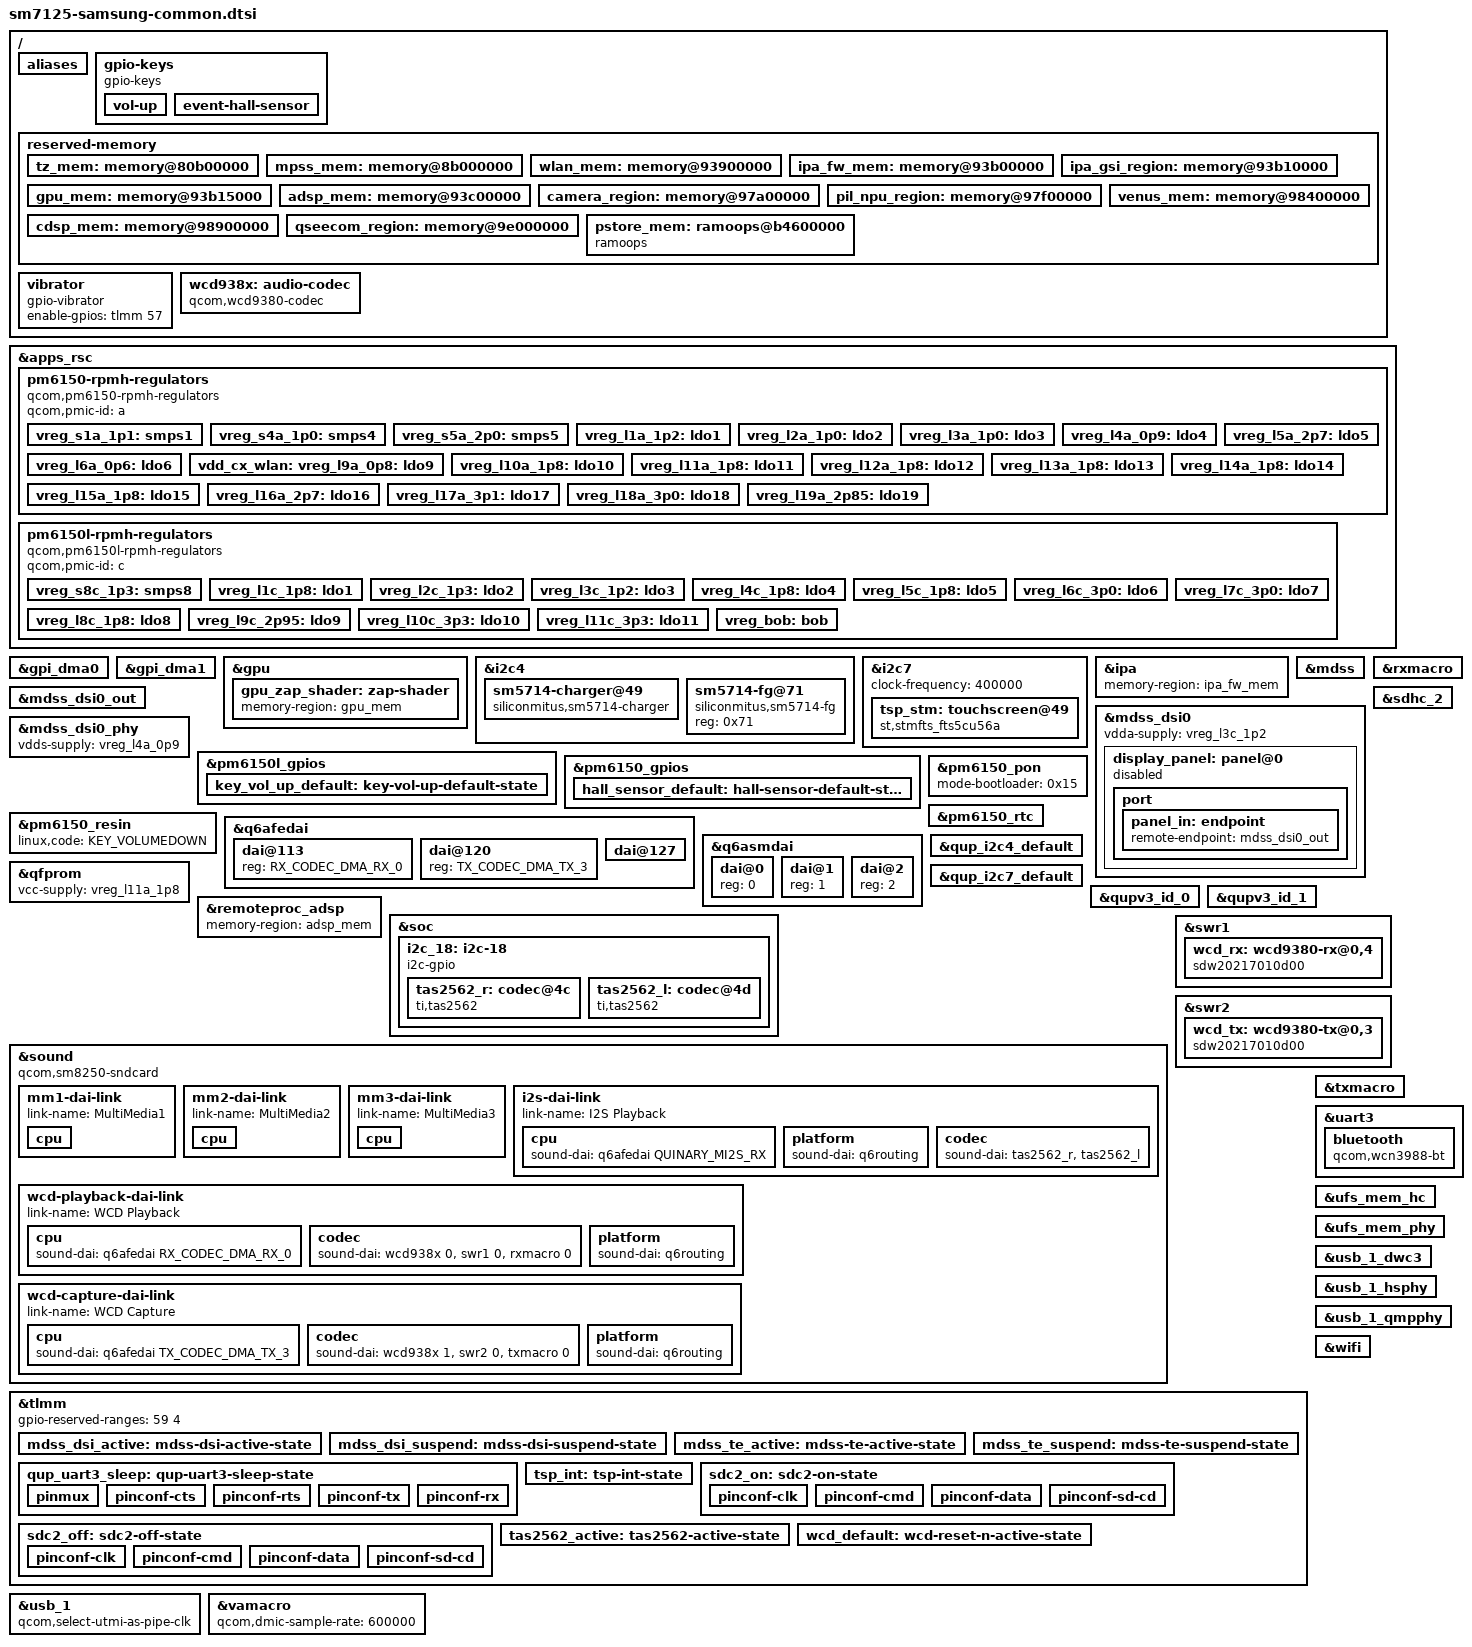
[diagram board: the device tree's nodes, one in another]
// SPDX-License-Identifier: GPL-2.0
/*
 * SM7125 Samsung common device tree source
 *
 * Copyright (c) 2021, The Linux Foundation. All rights reserved.
 */

#include <dt-bindings/arm/qcom,ids.h>
#include <dt-bindings/gpio/gpio.h>
#include <dt-bindings/regulator/qcom,rpmh-regulator.h>
#include <dt-bindings/pinctrl/qcom,pmic-gpio.h>
#include <dt-bindings/sound/qcom,q6asm.h>
#include "sm7125.dtsi"
#include "pm6150.dtsi"
#include "pm6150l.dtsi"

/delete-node/ &cdsp_mem;
/delete-node/ &rmtfs_mem;
/delete-node/ &ipa_fw_mem;
/delete-node/ &tz_mem;

/ {
	chassis-type = "handset";

	qcom,msm-id = <QCOM_ID_SM7125 0>;

	aliases {
		bluetooth0 = &bluetooth;
		hsuart0 = &uart3;
		i2c18 = &i2c_18;
		wifi0 = &wifi;
	};

	gpio-keys {
		compatible = "gpio-keys";

		pinctrl-names = "default";
		pinctrl-0 = <&key_vol_up_default>, <&hall_sensor_default>;

		vol-up {
			label = "Volume up";
			gpios = <&pm6150l_gpios 8 GPIO_ACTIVE_LOW>;
			linux,code = <KEY_VOLUMEUP>;
			debounce-interval = <15>;
			linux,can-disable;
			wakeup-source;
		};

		event-hall-sensor {
			label = "Hall Effect Sensor";
			gpios = <&pm6150_gpios 10 GPIO_ACTIVE_LOW>;
			linux,input-type = <EV_SW>;
			linux,code = <SW_LID>;
			debounce-interval = <15>;
			linux,can-disable;
			wakeup-source;
		};
	};

	reserved-memory {
		#address-cells = <2>;
		#size-cells = <2>;
		ranges;

		tz_mem: memory@80b00000 {
			reg = <0x0 0x80b00000 0x0 0x7100000>;
			no-map;
		};

		mpss_mem: memory@8b000000 {
			reg = <0x0 0x8b000000 0x0 0x8900000>;
			no-map;
		};

		wlan_mem: memory@93900000 {
			reg = <0x0 0x93900000 0x0 0x200000>;
			no-map;
		};

		ipa_fw_mem: memory@93b00000 {
			reg = <0x0 0x93b00000 0x0 0x10000>;
			no-map;
		};

		ipa_gsi_region: memory@93b10000 {
			reg = <0x0 0x93b10000 0x0 0x5000>;
			no-map;
		};

		gpu_mem: memory@93b15000 {
			reg = <0x0 0x93b15000 0x0 0x2000>;
			no-map;
		};

		adsp_mem: memory@93c00000 {
			reg = <0x0 0x93c00000 0x0 0x3e00000>;
			no-map;
		};

		camera_region: memory@97a00000 {
			reg = <0x0 0x97a00000 0x0 0x500000>;
			no-map;
		};

		pil_npu_region: memory@97f00000 {
			reg = <0x0 0x97f00000 0x0 0x500000>;
			no-map;
		};

		venus_mem: memory@98400000 {
			reg = <0x0 0x98400000 0x0 0x500000>;
			no-map;
		};

		cdsp_mem: memory@98900000 {
			reg = <0x0 0x98900000 0x0 0x1e00000>;
			no-map;
		};

		qseecom_region: memory@9e000000 {
			reg = <0x0 0x9e000000 0x0 0x2000000>;
			no-map;
		};

		pstore_mem: ramoops@b4600000 {
			compatible = "ramoops";
			reg = <0x0 0xb4600000 0x0 0x100000>;
			record-size = <0x40000>;
			console-size = <0x40000>;
			ftrace-size = <0x40000>;
			pmsg-size = <0x40000>;
		};
	};

	vibrator {
		compatible = "gpio-vibrator";
		enable-gpios = <&tlmm 57 GPIO_ACTIVE_HIGH>;
		pinctrl-names = "default";
	};

	wcd938x: audio-codec {
		compatible = "qcom,wcd9380-codec";

		pinctrl-names = "default";
		pinctrl-0 = <&wcd_default>;

		/* Samsung changes from downstream tree
		 * qcom,micbias2-microvolt = <2800000>;
		 * qcom,mbhc-buttons-vthreshold-microvolt = <13000 88000 138000 225000 450000 450000 450000 450000>;
		 * qcom,mbhc-headset-vthreshold-microvolt = <9999000>;
		 * qcom,mbhc-headphone-vthreshold-microvolt = <640000>;
		 */
		qcom,micbias1-microvolt = <1800000>;
		qcom,micbias2-microvolt = <1800000>;
		qcom,micbias3-microvolt = <1800000>;
		qcom,micbias4-microvolt = <1800000>;
		qcom,mbhc-buttons-vthreshold-microvolt = <75000 150000 237000 500000 500000 500000 500000 500000>;
		qcom,mbhc-headset-vthreshold-microvolt = <1700000>;
		qcom,mbhc-headphone-vthreshold-microvolt = <50000>;
		qcom,rx-device = <&wcd_rx>;
		qcom,tx-device = <&wcd_tx>;

		reset-gpios = <&tlmm 58 GPIO_ACTIVE_LOW>;

		vdd-buck-supply = <&vreg_l15a_1p8>;
		vdd-rxtx-supply = <&vreg_l10a_1p8>;
		vdd-io-supply = <&vreg_l10a_1p8>;
		vdd-mic-bias-supply = <&vreg_bob>;

		#sound-dai-cells = <1>;
	};
};

&apps_rsc {
	pm6150-rpmh-regulators {
		compatible = "qcom,pm6150-rpmh-regulators";
		qcom,pmic-id = "a";

		vreg_s1a_1p1: smps1 {
			regulator-min-microvolt = <1128000>;
			regulator-max-microvolt = <1128000>;
		};

		vreg_s4a_1p0: smps4 {
			regulator-min-microvolt = <824000>;
			regulator-max-microvolt = <1120000>;
		};

		vreg_s5a_2p0: smps5 {
			regulator-min-microvolt = <1744000>;
			regulator-max-microvolt = <2040000>;
		};

		vreg_l1a_1p2: ldo1 {
			regulator-min-microvolt = <1178000>;
			regulator-max-microvolt = <1256000>;
			regulator-initial-mode = <RPMH_REGULATOR_MODE_HPM>;
		};

		vreg_l2a_1p0: ldo2 {
			regulator-min-microvolt = <944000>;
			regulator-max-microvolt = <1056000>;
			regulator-initial-mode = <RPMH_REGULATOR_MODE_HPM>;
		};

		vreg_l3a_1p0: ldo3 {
			regulator-min-microvolt = <968000>;
			regulator-max-microvolt = <1064000>;
			regulator-initial-mode = <RPMH_REGULATOR_MODE_HPM>;
		};

		vreg_l4a_0p9: ldo4 {
			regulator-min-microvolt = <824000>;
			regulator-max-microvolt = <928000>;
			regulator-initial-mode = <RPMH_REGULATOR_MODE_HPM>;
			regulator-allow-set-load;
			regulator-allowed-modes = <RPMH_REGULATOR_MODE_LPM
						   RPMH_REGULATOR_MODE_HPM>;
		};

		/* Samsung changed this to 3.3v, but pmic(or mainline) doesn't support that... */
		vreg_l5a_2p7: ldo5 {
			regulator-min-microvolt = <2496000>;
			regulator-max-microvolt = <3000000>;
			regulator-initial-mode = <RPMH_REGULATOR_MODE_HPM>;
		};

		vreg_l6a_0p6: ldo6 {
			regulator-min-microvolt = <568000>;
			regulator-max-microvolt = <648000>;
			regulator-initial-mode = <RPMH_REGULATOR_MODE_HPM>;
		};

		/*vreg_l7a_0p9: ldo7 {
			regulator-min-microvolt = <900000>;
			regulator-max-microvolt = <900000>;
			regulator-initial-mode = <RPMH_REGULATOR_MODE_HPM>;
		};

		vreg_l8a_0p8: ldo8 {
			regulator-min-microvolt = <800000>;
			regulator-max-microvolt = <800000>;
			regulator-initial-mode = <RPMH_REGULATOR_MODE_HPM>;
		};*/

		vdd_cx_wlan:
		vreg_l9a_0p8: ldo9 {
			regulator-min-microvolt = <488000>;
			regulator-max-microvolt = <800000>;
			regulator-initial-mode = <RPMH_REGULATOR_MODE_HPM>;
		};

		vreg_l10a_1p8: ldo10 {
			regulator-min-microvolt = <1800000>;
			regulator-max-microvolt = <1832000>;
			regulator-initial-mode = <RPMH_REGULATOR_MODE_HPM>;
		};

		vreg_l11a_1p8: ldo11 {
			regulator-min-microvolt = <1696000>;
			regulator-max-microvolt = <1904000>;
			regulator-initial-mode = <RPMH_REGULATOR_MODE_HPM>;
		};

		vreg_l12a_1p8: ldo12 {
			regulator-min-microvolt = <1696000>;
			regulator-max-microvolt = <1952000>;
			regulator-initial-mode = <RPMH_REGULATOR_MODE_HPM>;
			regulator-allow-set-load;
			regulator-allowed-modes = <RPMH_REGULATOR_MODE_LPM
						   RPMH_REGULATOR_MODE_HPM>;
		};

		vreg_l13a_1p8: ldo13 {
			regulator-min-microvolt = <1696000>;
			regulator-max-microvolt = <1904000>;
			regulator-initial-mode = <RPMH_REGULATOR_MODE_HPM>;
		};

		vreg_l14a_1p8: ldo14 {
			regulator-min-microvolt = <1728000>;
			regulator-max-microvolt = <1832000>;
			regulator-initial-mode = <RPMH_REGULATOR_MODE_HPM>;
		};

		vreg_l15a_1p8: ldo15 {
			regulator-min-microvolt = <1696000>;
			regulator-max-microvolt = <1904000>;
			regulator-initial-mode = <RPMH_REGULATOR_MODE_HPM>;
		};

		vreg_l16a_2p7: ldo16 {
			regulator-min-microvolt = <2496000>;
			regulator-max-microvolt = <3304000>;
			regulator-initial-mode = <RPMH_REGULATOR_MODE_HPM>;
		};

		vreg_l17a_3p1: ldo17 {
			regulator-min-microvolt = <2920000>;
			regulator-max-microvolt = <3232000>;
			regulator-initial-mode = <RPMH_REGULATOR_MODE_HPM>;
		};

		vreg_l18a_3p0: ldo18 {
			regulator-min-microvolt = <2496000>;
			regulator-max-microvolt = <3304000>;
			regulator-initial-mode = <RPMH_REGULATOR_MODE_HPM>;
		};

		vreg_l19a_2p85: ldo19 {
			regulator-min-microvolt = <2696000>;
			regulator-max-microvolt = <3304000>;
			regulator-initial-mode = <RPMH_REGULATOR_MODE_HPM>;
			regulator-allow-set-load;
			regulator-allowed-modes = <RPMH_REGULATOR_MODE_LPM
						   RPMH_REGULATOR_MODE_HPM>;
		};
	};

	pm6150l-rpmh-regulators {
		compatible = "qcom,pm6150l-rpmh-regulators";
		qcom,pmic-id = "c";

		vreg_s8c_1p3: smps8 {
			regulator-min-microvolt = <1120000>;
			regulator-max-microvolt = <1408000>;
		};

		vreg_l1c_1p8: ldo1 {
			regulator-min-microvolt = <1616000>;
			regulator-max-microvolt = <1984000>;
			regulator-initial-mode = <RPMH_REGULATOR_MODE_HPM>;
		};

		vreg_l2c_1p3: ldo2 {
			regulator-min-microvolt = <1168000>;
			regulator-max-microvolt = <1304000>;
			regulator-initial-mode = <RPMH_REGULATOR_MODE_HPM>;
		};

		vreg_l3c_1p2: ldo3 {
			regulator-min-microvolt = <1144000>;
			regulator-max-microvolt = <1304000>;
			regulator-initial-mode = <RPMH_REGULATOR_MODE_HPM>;
			regulator-allow-set-load;
			regulator-allowed-modes = <RPMH_REGULATOR_MODE_LPM
						   RPMH_REGULATOR_MODE_HPM>;
		};


		vreg_l4c_1p8: ldo4 {
			regulator-min-microvolt = <1648000>;
			regulator-max-microvolt = <3304000>;
			regulator-initial-mode = <RPMH_REGULATOR_MODE_HPM>;
		};

		vreg_l5c_1p8: ldo5 {
			regulator-min-microvolt = <1648000>;
			regulator-max-microvolt = <3304000>;
			regulator-initial-mode = <RPMH_REGULATOR_MODE_HPM>;
		};

		vreg_l6c_3p0: ldo6 {
			regulator-min-microvolt = <1648000>;
			regulator-max-microvolt = <3304000>;
			regulator-initial-mode = <RPMH_REGULATOR_MODE_HPM>;
		};

		/* Samsung change for Touch IC */
		vreg_l7c_3p0: ldo7 {
			regulator-min-microvolt = <3000000>;
			regulator-max-microvolt = <3000000>;
			regulator-initial-mode = <RPMH_REGULATOR_MODE_HPM>;
		};

		/* Samsung change for Sensor IC's */
		vreg_l8c_1p8: ldo8 {
			regulator-min-microvolt = <1800000>;
			regulator-max-microvolt = <1800000>;
			regulator-initial-mode = <RPMH_REGULATOR_MODE_HPM>;
			regulator-always-on;
		};

		vreg_l9c_2p95: ldo9 {
			regulator-min-microvolt = <2952000>;
			regulator-max-microvolt = <3304000>;
			regulator-initial-mode = <RPMH_REGULATOR_MODE_HPM>;
		};

		vreg_l10c_3p3: ldo10 {
			regulator-min-microvolt = <3000000>;
			regulator-max-microvolt = <3400000>;
			regulator-initial-mode = <RPMH_REGULATOR_MODE_HPM>;
		};

		vreg_l11c_3p3: ldo11 {
			regulator-min-microvolt = <3000000>;
			regulator-max-microvolt = <3400000>;
			regulator-initial-mode = <RPMH_REGULATOR_MODE_HPM>;
		};

		vreg_bob: bob {
			regulator-min-microvolt = <3008000>;
			regulator-max-microvolt = <3960000>;
			regulator-initial-mode = <RPMH_REGULATOR_MODE_AUTO>;
		};
	};
};

&gpi_dma0 {
	status = "okay";
};

&gpi_dma1 {
	status = "okay";
};

&gpu {
	status = "okay";

	gpu_zap_shader: zap-shader {
		memory-region = <&gpu_mem>;
	};
};

&i2c4 {
	status = "okay";

	sm5714-charger@49 {
		compatible = "siliconmitus,sm5714-charger";
		reg = <0x49>;

		siliconmitus,enable-autostop;
		siliconmitus,input-current-limit = <1300>;
		siliconmitus,charging-current = <1300>;
		siliconmitus,topoff-current = <225>;
	};

	sm5714-fg@71 {
		compatible = "siliconmitus,sm5714-fg";
		reg = <0x71>;
	};
};

&i2c7 {
	status = "okay";
	clock-frequency = <400000>;

	tsp_stm: touchscreen@49 {
		compatible = "st,stmfts_fts5cu56a";
		reg = <0x49>;

		pinctrl-names = "default";
		pinctrl-0 = <&tsp_int>;

		interrupt-parent = <&tlmm>;
		interrupts = <9 0x2008>;

		vdd-supply = <&vreg_l10a_1p8>;
		avdd-supply = <&vreg_l7c_3p0>;
	};
};

&ipa {
	memory-region = <&ipa_fw_mem>;
};

&mdss {
	status = "okay";
};

&mdss_dsi0 {
	vdda-supply = <&vreg_l3c_1p2>;
	status = "okay";

	display_panel: panel@0 {
		reg = <0>;

		pinctrl-names = "default", "sleep";
		pinctrl-0 = <&mdss_dsi_active>, <&mdss_te_active>;
		pinctrl-1 = <&mdss_dsi_suspend>, <&mdss_te_suspend>;

		vddio-supply = <&vreg_l13a_1p8>;
		vci-supply = <&vreg_l18a_3p0>;

		reset-gpios = <&tlmm 8 GPIO_ACTIVE_LOW>;

		status = "disabled";

		port {
			panel_in: endpoint {
				remote-endpoint = <&mdss_dsi0_out>;
			};
		};
	};
};

&mdss_dsi0_out {
	remote-endpoint = <&panel_in>;
	data-lanes = <0 1 2 3>;
};

&mdss_dsi0_phy {
	vdds-supply = <&vreg_l4a_0p9>;
	status = "okay";
};

&pm6150l_gpios {
	key_vol_up_default: key-vol-up-default-state {
		pins = "gpio8";
		function = "normal";
		input-enable;
		bias-pull-up;
		power-source = <0>;
	};
};

&pm6150_gpios {
	hall_sensor_default: hall-sensor-default-state {
		pins = "gpio10";
		function = "normal";
		output-disable;
		bias-disable;
		power-source = <0>;
	};
};

&pm6150_pon {
	/* LinuxLoader fastboot implementation has most of it's commands removed
	 * by Samsung, making it useless. So reboot to Odin download mode instead.
	 */
	mode-bootloader = <0x15>;
};

&pm6150_resin {
	linux,code = <KEY_VOLUMEDOWN>;
	status = "okay";
};

&pm6150_rtc {
	status = "okay";
};

&q6afedai {
	dai@113 {
		reg = <RX_CODEC_DMA_RX_0>;
	};

	dai@120 {
		reg = <TX_CODEC_DMA_TX_3>;
	};

	dai@127 {
		reg = <QUINARY_MI2S_RX>;
		qcom,sd-lines = <0>;
	};
};

&q6asmdai {
	dai@0 {
		reg = <0>;
	};

	dai@1 {
		reg = <1>;
	};

	dai@2 {
		reg = <2>;
	};
};

&qfprom {
	vcc-supply = <&vreg_l11a_1p8>;
};

&qup_i2c4_default {
	drive-strength = <2>;
	bias-disable;
};

&qup_i2c7_default {
	drive-strength = <2>;
	bias-disable;
};

&qupv3_id_0 {
	status = "okay";
};

&qupv3_id_1 {
	status = "okay";
};

&remoteproc_adsp {
	memory-region = <&adsp_mem>;
};

&rxmacro {
	status = "okay";
};

&sdhc_2 {
	pinctrl-names = "default", "sleep";
	pinctrl-0 = <&sdc2_on>;
	pinctrl-1 = <&sdc2_off>;
	vmmc-supply = <&vreg_l9c_2p95>;
	vqmmc-supply = <&vreg_l6c_3p0>;

	cd-gpios = <&tlmm 69 GPIO_ACTIVE_LOW>;
	status = "okay";
};

&soc {
	i2c_18: i2c-18 {
		compatible = "i2c-gpio";
		#address-cells = <1>;
		#size-cells = <0>;
		sda-gpios = <&tlmm 88 (GPIO_ACTIVE_HIGH|GPIO_OPEN_DRAIN)>;
		scl-gpios = <&tlmm 89 (GPIO_ACTIVE_HIGH|GPIO_OPEN_DRAIN)>;
		pinctrl-names = "default";
		pinctrl-0 = <&tas2562_active>;
		i2c-gpio,delay-us = <2>;

		tas2562_r: codec@4c {
			compatible = "ti,tas2562";
			reg = <0x4c>;
			#sound-dai-cells = <0>;
			interrupt-parent = <&tlmm>;
			interrupts = <90 IRQ_TYPE_NONE>;
			shutdown-gpios = <&tlmm 94 GPIO_ACTIVE_HIGH>;
			sound-name-prefix = "Right";
			ti,vmon-slot-no = <1>;
			ti,imon-slot-no = <0>;
		};

		tas2562_l: codec@4d {
			compatible = "ti,tas2562";
			reg = <0x4d>;
			#sound-dai-cells = <0>;
			interrupt-parent = <&tlmm>;
			interrupts = <90 IRQ_TYPE_NONE>;
			shutdown-gpios = <&tlmm 94 GPIO_ACTIVE_HIGH>;
			sound-name-prefix = "Left";
			ti,vmon-slot-no = <1>;
			ti,imon-slot-no = <0>;
		};
	};
};

&sound {
	compatible = "qcom,sm8250-sndcard";
	pinctrl-0 = <&i2s1_active>;
	pinctrl-names = "default";
	audio-routing =
		"IN1_HPHL", "HPHL_OUT",
		"IN2_HPHR", "HPHR_OUT",
		"AMIC1", "MIC BIAS1",
		"AMIC2", "MIC BIAS2",
		"AMIC4", "MIC BIAS3",
		"TX SWR_ADC0", "ADC1_OUTPUT",
		"TX SWR_ADC1", "ADC2_OUTPUT",
		"TX SWR_ADC3", "ADC4_OUTPUT";

	mm1-dai-link {
		link-name = "MultiMedia1";
		cpu {
			sound-dai = <&q6asmdai MSM_FRONTEND_DAI_MULTIMEDIA1>;
		};
	};

	mm2-dai-link {
		link-name = "MultiMedia2";
		cpu {
			sound-dai = <&q6asmdai MSM_FRONTEND_DAI_MULTIMEDIA2>;
		};
	};

	mm3-dai-link {
		link-name = "MultiMedia3";
		cpu {
			sound-dai = <&q6asmdai MSM_FRONTEND_DAI_MULTIMEDIA3>;
		};
	};

	i2s-dai-link {
		link-name = "I2S Playback";
		cpu {
			sound-dai = <&q6afedai QUINARY_MI2S_RX>;
		};

		platform {
			sound-dai = <&q6routing>;
		};

		codec {
			sound-dai = <&tas2562_r>, <&tas2562_l>;
		};
	};

	wcd-playback-dai-link {
		link-name = "WCD Playback";
		cpu {
			sound-dai = <&q6afedai RX_CODEC_DMA_RX_0>;
		};

		codec {
			sound-dai = <&wcd938x 0>, <&swr1 0>, <&rxmacro 0>;
		};

		platform {
			sound-dai = <&q6routing>;
		};
	};

	wcd-capture-dai-link {
		link-name = "WCD Capture";
		cpu {
			sound-dai = <&q6afedai TX_CODEC_DMA_TX_3>;
		};

		codec {
			sound-dai = <&wcd938x 1>, <&swr2 0>, <&txmacro 0>;
		};

		platform {
			sound-dai = <&q6routing>;
		};
	};
};

&swr1 {
	status = "okay";

	wcd_rx: wcd9380-rx@0,4 {
		compatible = "sdw20217010d00";
		reg = <0 4>;

		/*
		 * WCD9380 RX Port 1 (HPH_L/R)      <=> SWR1 Port 1 (HPH_L/R)
		 * WCD9380 RX Port 2 (CLSH)         <=> SWR1 Port 2 (CLSH)
		 * WCD9380 RX Port 3 (COMP_L/R)     <=> SWR1 Port 3 (COMP_L/R)
		 * WCD9380 RX Port 4 (LO)           <=> SWR1 Port 4 (LO)
		 * WCD9380 RX Port 5 (DSD_L/R)      <=> SWR1 Port 5 (DSD_L/R)
		 */
		qcom,rx-port-mapping = <1 2 3 4 5>;
	};
};

&swr2 {
	status = "okay";

	wcd_tx: wcd9380-tx@0,3 {
		compatible = "sdw20217010d00";
		reg = <0 3>;

		/*
		 * WCD9380 TX Port 1 (ADC1,2)             <=> SWR2 Port 2 (TX SWR_INPUT 0,1,2,3)
		 * WCD9380 TX Port 2 (ADC3,4)             <=> SWR2 Port 3 (TX SWR_INPUT 4,5,6,7)
		 * WCD9380 TX Port 3 (DMIC0,1,2,3 & MBHC) <=> SWR2 Port 4 (TX SWR_INPUT 8,9,10,11)
		 * WCD9380 TX Port 4 (DMIC4,5,6,7)        <=> SWR2 Port 5 (TX SWR_INPUT 12,13,14,15)
		 */
		qcom,tx-port-mapping = <2 3 4 5>;
	};
};

&tlmm {
	gpio-reserved-ranges = <59 4>;

	mdss_dsi_active: mdss-dsi-active-state {
		pins = "gpio8";
		function = "gpio";
		drive-strength = <8>;
		bias-disable;
	};

	mdss_dsi_suspend: mdss-dsi-suspend-state {
		pins = "gpio8";
		function = "gpio";
		drive-strength = <2>;
		bias-pull-down;
	};

	mdss_te_active: mdss-te-active-state {
		pins = "gpio10";
		function = "mdp_vsync";
		drive-strength = <2>;
		bias-pull-down;
	};

	mdss_te_suspend: mdss-te-suspend-state {
		pins = "gpio10";
		function = "mdp_vsync";
		drive-strength = <2>;
		bias-pull-down;
	};

	qup_uart3_sleep: qup-uart3-sleep-state {
		pinmux {
			pins = "gpio38", "gpio39",
				"gpio40", "gpio41";
			function = "gpio";
		};

		pinconf-cts {
			/*
			 * Configure a pull-down on CTS to match the pull of
			 * the Bluetooth module.
			 */
			pins = "gpio38";
			bias-pull-down;
		};

		pinconf-rts {
			/*
			 * Configure pull-down on RTS. As RTS is active low
			 * signal, pull it low to indicate the BT SoC that it
			 * can wakeup the system anytime from suspend state by
			 * pulling RX low (by sending wakeup bytes).
			 */
			pins = "gpio39";
			bias-pull-down;
		};

		pinconf-tx {
			/*
			 * Configure pull-up on TX when it isn't actively driven
			 * to prevent BT SoC from receiving garbage during sleep.
			 */
			pins = "gpio40";
			bias-pull-up;
		};

		pinconf-rx {
			/*
			 * Configure a pull-up on RX. This is needed to avoid
			 * garbage data when the TX pin of the Bluetooth module
			 * is floating which may cause spurious wakeups.
			 */
			pins = "gpio41";
			bias-pull-up;
		};
	};

	tsp_int: tsp-int-state {
		pins = "gpio9";
		function = "gpio";
		input-enable;
		bias-disable;
	};

	sdc2_on: sdc2-on-state {
		pinconf-clk {
			pins = "sdc2_clk";
			bias-disable;
			drive-strength = <16>;
		};

		pinconf-cmd {
			pins = "sdc2_cmd";
			bias-pull-up;
			drive-strength = <10>;
		};

		pinconf-data {
			pins = "sdc2_data";
			bias-pull-up;
			drive-strength = <10>;
		};

		pinconf-sd-cd {
			pins = "gpio69";
			bias-pull-up;
			drive-strength = <2>;
		};
	};

	sdc2_off: sdc2-off-state {
		pinconf-clk {
			pins = "sdc2_clk";
			bias-disable;
			drive-strength = <2>;
		};

		pinconf-cmd {
			pins = "sdc2_cmd";
			bias-pull-up;
			drive-strength = <2>;
		};

		pinconf-data {
			pins = "sdc2_data";
			bias-pull-up;
			drive-strength = <2>;
		};

		pinconf-sd-cd {
			pins = "gpio69";
			bias-pull-up;
			drive-strength = <2>;
		};
	};

	tas2562_active: tas2562-active-state {
		/* SDA, SCL, INT, EN */
		pins = "gpio88", "gpio89", "gpio90", "gpio94";
		function = "gpio";
		bias-disable;
	};

	wcd_default: wcd-reset-n-active-state {
		pins = "gpio58";
		function = "gpio";
		drive-strength = <16>;
		bias-disable;
		output-low;
	};
};

&txmacro {
	status = "okay";
};

&uart3 {
	/delete-property/interrupts;
	interrupts-extended = <&intc GIC_SPI 604 IRQ_TYPE_LEVEL_HIGH>,
				<&tlmm 41 IRQ_TYPE_EDGE_FALLING>;

	pinctrl-names = "default", "sleep";
	pinctrl-1 = <&qup_uart3_sleep>;

	status = "okay";

	bluetooth: bluetooth {
		compatible = "qcom,wcn3988-bt";

		local-bd-address = [ 22 00 00 00 5a ad ];

		vddio-supply = <&vreg_l10a_1p8>;
		vddxo-supply = <&vreg_l1c_1p8>;
		vddrf-supply = <&vreg_l2c_1p3>;
		vddch0-supply = <&vreg_l10c_3p3>;
		swctrl-gpios = <&tlmm 73 GPIO_ACTIVE_HIGH>;

		max-speed = <3200000>;
	};
};

&ufs_mem_hc {
	vcc-supply = <&vreg_l19a_2p85>;
	vcc-max-microamp = <600000>;
	vccq2-supply = <&vreg_l12a_1p8>;
	vccq2-max-microamp = <600000>;
	status = "okay";
};

&ufs_mem_phy {
	vdda-phy-supply = <&vreg_l4a_0p9>;
	vdda-pll-supply = <&vreg_l3c_1p2>;
	status = "okay";
};

&usb_1 {
	qcom,select-utmi-as-pipe-clk;
	status = "okay";
};

&usb_1_dwc3 {
	dr_mode = "peripheral";
	maximum-speed = "high-speed";
};

&usb_1_hsphy {
	vdd-supply = <&vreg_l4a_0p9>;
	vdda-pll-supply = <&vreg_l11a_1p8>;
	vdda-phy-dpdm-supply = <&vreg_l17a_3p1>;
	status = "okay";
};

&usb_1_qmpphy {
	vdda-phy-supply = <&vreg_l4a_0p9>;
	vdda-pll-supply = <&vreg_l3c_1p2>;
	status = "okay";
};

&vamacro {
	qcom,dmic-sample-rate = <600000>;
	status = "okay";
};

&wifi {
	vdd-0.8-cx-mx-supply = <&vreg_l9a_0p8>;
	vdd-1.8-xo-supply = <&vreg_l1c_1p8>;
	vdd-1.3-rfa-supply = <&vreg_l2c_1p3>;
	vdd-3.3-ch0-supply = <&vreg_l10c_3p3>;
	vdd-3.3-ch1-supply = <&vreg_l11c_3p3>;
	status = "okay";
};
